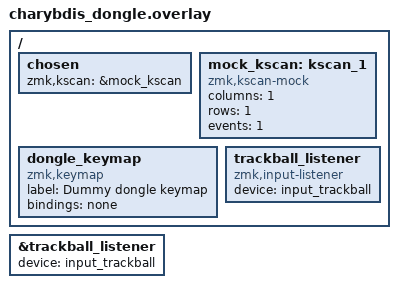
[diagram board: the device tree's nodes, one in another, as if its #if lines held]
// Documentation: https://zmk.dev/docs/development/hardware-integration/dongle#building-the-firmware
#include "charybdis_pointer.dtsi"

/ {
    chosen {
        zmk,kscan = &mock_kscan;
    };

    // Create mock layout and keymap to prevent linking errors on dongle build
    mock_kscan: kscan_1 {
        compatible = "zmk,kscan-mock";
        columns = <1>;
        rows = <1>;
        events = <1>;
    };

    dongle_keymap {
        compatible = "zmk,keymap";
        label = "Dummy dongle keymap";
        bindings = <&none>;
    };

    #ifdef CONFIG_ZMK_SPLIT_ROLE_CENTRAL
    trackball_listener {
        compatible = "zmk,input-listener";
        device = <&input_trackball>;
    };
    #endif
};


&trackball_listener {
  status           = "okay";
  device           = <&input_trackball>;
  /* …input-processors & processor-layers… */
};
